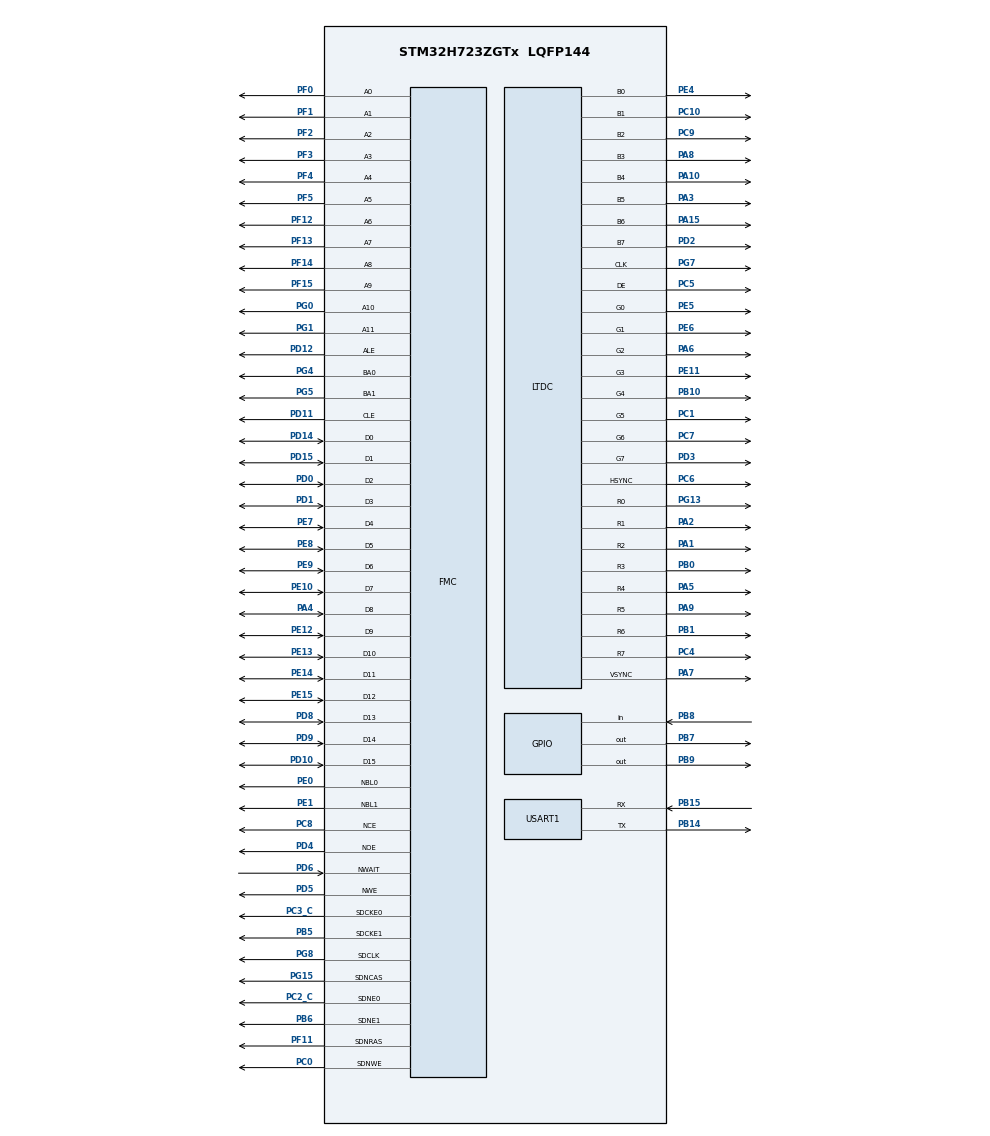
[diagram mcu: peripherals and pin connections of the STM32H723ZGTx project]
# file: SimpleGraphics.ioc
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CORTEX_M7.default_mode_Activation=1
DMA2D.AlphaModeForeground=DMA2D_COMBINE_ALPHA
Dma.MEMTOMEM.2.Direction=DMA_MEMORY_TO_MEMORY
Dma.MEMTOMEM.2.EventEnable=DISABLE
Dma.MEMTOMEM.2.FIFOMode=DMA_FIFOMODE_ENABLE
Dma.MEMTOMEM.2.FIFOThreshold=DMA_FIFO_THRESHOLD_FULL
Dma.MEMTOMEM.2.Instance=DMA1_Stream2
Dma.MEMTOMEM.2.MemBurst=DMA_MBURST_SINGLE
Dma.MEMTOMEM.2.MemDataAlignment=DMA_MDATAALIGN_BYTE
Dma.MEMTOMEM.2.MemInc=DMA_MINC_ENABLE
Dma.MEMTOMEM.2.Mode=DMA_NORMAL
Dma.MEMTOMEM.2.PeriphBurst=DMA_PBURST_SINGLE
Dma.MEMTOMEM.2.PeriphDataAlignment=DMA_PDATAALIGN_BYTE
Dma.MEMTOMEM.2.PeriphInc=DMA_PINC_ENABLE
Dma.MEMTOMEM.2.Polarity=HAL_DMAMUX_REQ_GEN_RISING
Dma.MEMTOMEM.2.Priority=DMA_PRIORITY_VERY_HIGH
Dma.MEMTOMEM.2.RequestNumber=1
Dma.MEMTOMEM.2.SignalID=NONE
Dma.MEMTOMEM.2.SyncEnable=DISABLE
Dma.MEMTOMEM.2.SyncPolarity=HAL_DMAMUX_SYNC_NO_EVENT
Dma.MEMTOMEM.2.SyncRequestNumber=1
Dma.MEMTOMEM.2.SyncSignalID=NONE
Dma.MEMTOMEM.3.Direction=DMA_MEMORY_TO_MEMORY
Dma.MEMTOMEM.3.EventEnable=DISABLE
Dma.MEMTOMEM.3.FIFOMode=DMA_FIFOMODE_ENABLE
Dma.MEMTOMEM.3.FIFOThreshold=DMA_FIFO_THRESHOLD_FULL
Dma.MEMTOMEM.3.Instance=DMA1_Stream3
Dma.MEMTOMEM.3.MemBurst=DMA_MBURST_SINGLE
Dma.MEMTOMEM.3.MemDataAlignment=DMA_MDATAALIGN_BYTE
Dma.MEMTOMEM.3.MemInc=DMA_MINC_ENABLE
Dma.MEMTOMEM.3.Mode=DMA_NORMAL
Dma.MEMTOMEM.3.PeriphBurst=DMA_PBURST_SINGLE
Dma.MEMTOMEM.3.PeriphDataAlignment=DMA_PDATAALIGN_BYTE
Dma.MEMTOMEM.3.PeriphInc=DMA_PINC_ENABLE
Dma.MEMTOMEM.3.Polarity=HAL_DMAMUX_REQ_GEN_RISING
Dma.MEMTOMEM.3.Priority=DMA_PRIORITY_VERY_HIGH
Dma.MEMTOMEM.3.RequestNumber=1
Dma.MEMTOMEM.3.SignalID=NONE
Dma.MEMTOMEM.3.SyncEnable=DISABLE
Dma.MEMTOMEM.3.SyncPolarity=HAL_DMAMUX_SYNC_NO_EVENT
Dma.MEMTOMEM.3.SyncRequestNumber=1
Dma.MEMTOMEM.3.SyncSignalID=NONE
Dma.MEMTOMEM.4.Direction=DMA_MEMORY_TO_MEMORY
Dma.MEMTOMEM.4.EventEnable=DISABLE
Dma.MEMTOMEM.4.FIFOMode=DMA_FIFOMODE_ENABLE
Dma.MEMTOMEM.4.FIFOThreshold=DMA_FIFO_THRESHOLD_FULL
Dma.MEMTOMEM.4.Instance=DMA1_Stream4
Dma.MEMTOMEM.4.MemBurst=DMA_MBURST_SINGLE
Dma.MEMTOMEM.4.MemDataAlignment=DMA_MDATAALIGN_BYTE
Dma.MEMTOMEM.4.MemInc=DMA_MINC_ENABLE
Dma.MEMTOMEM.4.Mode=DMA_NORMAL
Dma.MEMTOMEM.4.PeriphBurst=DMA_PBURST_SINGLE
Dma.MEMTOMEM.4.PeriphDataAlignment=DMA_PDATAALIGN_BYTE
Dma.MEMTOMEM.4.PeriphInc=DMA_PINC_ENABLE
Dma.MEMTOMEM.4.Polarity=HAL_DMAMUX_REQ_GEN_RISING
Dma.MEMTOMEM.4.Priority=DMA_PRIORITY_VERY_HIGH
Dma.MEMTOMEM.4.RequestNumber=1
Dma.MEMTOMEM.4.SignalID=NONE
Dma.MEMTOMEM.4.SyncEnable=DISABLE
Dma.MEMTOMEM.4.SyncPolarity=HAL_DMAMUX_SYNC_NO_EVENT
Dma.MEMTOMEM.4.SyncRequestNumber=1
Dma.MEMTOMEM.4.SyncSignalID=NONE
Dma.Request0=USART1_RX
Dma.Request1=USART1_TX
Dma.Request2=MEMTOMEM
Dma.Request3=MEMTOMEM
Dma.Request4=MEMTOMEM
Dma.USART1_RX.0.Direction=DMA_PERIPH_TO_MEMORY
Dma.USART1_RX.0.EventEnable=DISABLE
Dma.USART1_RX.0.FIFOMode=DMA_FIFOMODE_DISABLE
Dma.USART1_RX.0.Instance=DMA1_Stream0
Dma.USART1_RX.0.MemDataAlignment=DMA_MDATAALIGN_BYTE
Dma.USART1_RX.0.MemInc=DMA_MINC_ENABLE
Dma.USART1_RX.0.Mode=DMA_NORMAL
Dma.USART1_RX.0.PeriphDataAlignment=DMA_PDATAALIGN_BYTE
Dma.USART1_RX.0.PeriphInc=DMA_PINC_DISABLE
Dma.USART1_RX.0.Polarity=HAL_DMAMUX_REQ_GEN_RISING
Dma.USART1_RX.0.Priority=DMA_PRIORITY_VERY_HIGH
Dma.USART1_RX.0.RequestNumber=1
Dma.USART1_RX.0.SignalID=NONE
Dma.USART1_RX.0.SyncEnable=DISABLE
Dma.USART1_RX.0.SyncPolarity=HAL_DMAMUX_SYNC_NO_EVENT
Dma.USART1_RX.0.SyncRequestNumber=1
Dma.USART1_RX.0.SyncSignalID=NONE
Dma.USART1_TX.1.Direction=DMA_MEMORY_TO_PERIPH
Dma.USART1_TX.1.EventEnable=DISABLE
Dma.USART1_TX.1.FIFOMode=DMA_FIFOMODE_DISABLE
Dma.USART1_TX.1.Instance=DMA1_Stream1
Dma.USART1_TX.1.MemDataAlignment=DMA_MDATAALIGN_BYTE
Dma.USART1_TX.1.MemInc=DMA_MINC_ENABLE
Dma.USART1_TX.1.Mode=DMA_NORMAL
Dma.USART1_TX.1.PeriphDataAlignment=DMA_PDATAALIGN_BYTE
Dma.USART1_TX.1.PeriphInc=DMA_PINC_DISABLE
Dma.USART1_TX.1.Polarity=HAL_DMAMUX_REQ_GEN_RISING
Dma.USART1_TX.1.Priority=DMA_PRIORITY_VERY_HIGH
Dma.USART1_TX.1.RequestNumber=1
Dma.USART1_TX.1.SignalID=NONE
Dma.USART1_TX.1.SyncEnable=DISABLE
Dma.USART1_TX.1.SyncPolarity=HAL_DMAMUX_SYNC_NO_EVENT
Dma.USART1_TX.1.SyncRequestNumber=1
Dma.USART1_TX.1.SyncSignalID=NONE
LTDC.DEPolarity=LTDC_DEPOLARITY_AH
LTDC.HSPolarity=LTDC_HSPOLARITY_AH
LTDC.PCPolarity=LTDC_PCPOLARITY_IPC
LTDC.VSPolarity=LTDC_VSPOLARITY_AH
Mcu.Family=STM32H7
Mcu.Name=STM32H723ZGTx
Mcu.Package=LQFP144
NVIC.DMA1_Stream0_IRQn=true\:0\:0\:false\:false\:true\:false\:true\:true
NVIC.DMA1_Stream1_IRQn=true\:0\:0\:false\:false\:true\:false\:true\:true
NVIC.DMA2D_IRQn=true\:0\:0\:false\:false\:true\:true\:true\:true
NVIC.FMC_IRQn=true\:0\:0\:false\:false\:true\:true\:true\:true
NVIC.LTDC_IRQn=true\:0\:0\:false\:false\:true\:true\:true\:true
NVIC.PriorityGroup=NVIC_PRIORITYGROUP_4
NVIC.USART1_IRQn=true\:0\:0\:false\:false\:true\:true\:true\:true
PA1.Mode=RGB888
PA1.Signal=LTDC_R2
PA10.Mode=RGB888
PA10.Signal=LTDC_B4
PA15(JTDI).Mode=RGB888
PA15(JTDI).Signal=LTDC_B6
PA2.Mode=RGB888
PA2.Signal=LTDC_R1
PA3.Mode=RGB888
PA3.Signal=LTDC_B5
PA4.Signal=FMC_D8_DA8
PA5.Mode=RGB888
PA5.Signal=LTDC_R4
PA6.Mode=RGB888
PA6.Signal=LTDC_G2
PA7.Mode=RGB888
PA7.Signal=LTDC_VSYNC
PA8.Mode=RGB888
PA8.Signal=LTDC_B3
PA9.Mode=RGB888
PA9.Signal=LTDC_R5
PB0.Mode=RGB888
PB0.Signal=LTDC_R3
PB1.Mode=RGB888
PB1.Signal=LTDC_R6
PB10.Mode=RGB888
PB10.Signal=LTDC_G4
PB14.Mode=Asynchronous
PB14.Signal=USART1_TX
PB15.Mode=Asynchronous
PB15.Signal=USART1_RX
PB5.Mode=SdramChipSelect2_2
PB5.Signal=FMC_SDCKE1
PB6.Mode=SdramChipSelect2_2
PB6.Signal=FMC_SDNE1
PB7.Signal=GPIO_Output
PB8.Signal=GPIO_Input
PB9.Signal=GPIO_Output
PC0.Signal=FMC_SDNWE
PC1.Mode=RGB888
PC1.Signal=LTDC_G5
PC10.Mode=RGB888
PC10.Signal=LTDC_B1
PC14-OSC32_IN.Mode=LSE-External-Oscillator
PC14-OSC32_IN.Signal=RCC_OSC32_IN
PC15-OSC32_OUT.Mode=LSE-External-Oscillator
PC15-OSC32_OUT.Signal=RCC_OSC32_OUT
PC2_C.Mode=SdramChipSelect1_1
PC2_C.Signal=FMC_SDNE0
PC3_C.Mode=SdramChipSelect1_1
PC3_C.Signal=FMC_SDCKE0
PC4.Mode=RGB888
PC4.Signal=LTDC_R7
PC5.Mode=RGB888
PC5.Signal=LTDC_DE
PC6.Mode=RGB888
PC6.Signal=LTDC_HSYNC
PC7.Mode=RGB888
PC7.Signal=LTDC_G6
PC8.Mode=NandChipSelect3_1
PC8.Signal=FMC_NCE
PC9.Mode=RGB888
PC9.Signal=LTDC_B2
PD0.Signal=FMC_D2_DA2
PD1.Signal=FMC_D3_DA3
PD10.Signal=FMC_D15_DA15
PD11.Signal=FMC_A16_CLE
PD12.Signal=FMC_A17_ALE
PD14.Signal=FMC_D0_DA0
PD15.Signal=FMC_D1_DA1
PD2.Mode=RGB888
PD2.Signal=LTDC_B7
PD3.Mode=RGB888
PD3.Signal=LTDC_G7
PD4.Signal=FMC_NOE
PD5.Signal=FMC_NWE
PD6.Signal=FMC_NWAIT
PD8.Signal=FMC_D13_DA13
PD9.Signal=FMC_D14_DA14
PE0.Signal=FMC_NBL0
PE1.Signal=FMC_NBL1
PE10.Signal=FMC_D7_DA7
PE11.Mode=RGB888
PE11.Signal=LTDC_G3
PE12.Signal=FMC_D9_DA9
PE13.Signal=FMC_D10_DA10
PE14.Signal=FMC_D11_DA11
PE15.Signal=FMC_D12_DA12
PE4.Mode=RGB888
PE4.Signal=LTDC_B0
PE5.Mode=RGB888
PE5.Signal=LTDC_G0
PE6.Mode=RGB888
PE6.Signal=LTDC_G1
PE7.Signal=FMC_D4_DA4
PE8.Signal=FMC_D5_DA5
PE9.Signal=FMC_D6_DA6
PF0.Signal=FMC_A0
PF1.Signal=FMC_A1
PF11.Signal=FMC_SDNRAS
PF12.Signal=FMC_A6
PF13.Signal=FMC_A7
PF14.Signal=FMC_A8
PF15.Signal=FMC_A9
PF2.Signal=FMC_A2
PF3.Signal=FMC_A3
PF4.Signal=FMC_A4
PF5.Signal=FMC_A5
PG0.Signal=FMC_A10
PG1.Signal=FMC_A11
PG13.Mode=RGB888
PG13.Signal=LTDC_R0
PG15.Signal=FMC_SDNCAS
PG4.Signal=FMC_A14_BA0
PG5.Signal=FMC_A15_BA1
PG7.Mode=RGB888
PG7.Signal=LTDC_CLK
PG8.Signal=FMC_SDCLK
PH0-OSC_IN.Mode=HSE-External-Oscillator
PH0-OSC_IN.Signal=RCC_OSC_IN
PH1-OSC_OUT.Mode=HSE-External-Oscillator
PH1-OSC_OUT.Signal=RCC_OSC_OUT
ProjectManager.HeapSize=0x1000
ProjectManager.StackSize=0x1000
ProjectManager.TargetToolchain=Makefile
RCC.ADCFreq_Value=50390625
RCC.APB1Freq_Value=137500000
RCC.APB2Freq_Value=137500000
RCC.APB3Freq_Value=137500000
RCC.APB4Freq_Value=137500000
RCC.CortexFreq_Value=550000000
RCC.D1PPRE=RCC_APB3_DIV2
RCC.D2PPRE1=RCC_APB1_DIV2
RCC.D2PPRE2=RCC_APB2_DIV2
RCC.D3PPRE=RCC_APB4_DIV2
RCC.DIVM1=2
RCC.DIVM3=1
RCC.DIVN1=44
RCC.DIVN3=4
RCC.DIVP1=1
RCC.DIVQ1=5
RCC.HCLKFreq_Value=275000000
RCC.HPRE=RCC_HCLK_DIV2
RCC.PLL2FRACN=0
RCC.PLL3FRACN=0
RCC.PLLFRACN=0
RCC.PLLSourceVirtual=RCC_PLLSOURCE_HSE
RCC.SYSCLKFreq_VALUE=550000000
RCC.SYSCLKSource=RCC_SYSCLKSOURCE_PLLCLK
RCC.USBFreq_Value=110000000
SH.FMC_A0.0=FMC_A0,12b-sda1
SH.FMC_A0.1=FMC_A0,12b-sda2
SH.FMC_A1.0=FMC_A1,12b-sda1
SH.FMC_A1.1=FMC_A1,12b-sda2
SH.FMC_A10.0=FMC_A10,12b-sda1
SH.FMC_A10.1=FMC_A10,12b-sda2
SH.FMC_A11.0=FMC_A11,12b-sda1
SH.FMC_A11.1=FMC_A11,12b-sda2
SH.FMC_A14_BA0.0=FMC_BA0,FourSdramBanks1
SH.FMC_A14_BA0.1=FMC_BA0,FourSdramBanks2
SH.FMC_A15_BA1.0=FMC_BA1,FourSdramBanks1
SH.FMC_A15_BA1.1=FMC_BA1,FourSdramBanks2
SH.FMC_A16_CLE.0=FMC_CLE,8b-dmux1
SH.FMC_A17_ALE.0=FMC_ALE,8b-dmux1
SH.FMC_A2.0=FMC_A2,12b-sda1
SH.FMC_A2.1=FMC_A2,12b-sda2
SH.FMC_A3.0=FMC_A3,12b-sda1
SH.FMC_A3.1=FMC_A3,12b-sda2
SH.FMC_A4.0=FMC_A4,12b-sda1
SH.FMC_A4.1=FMC_A4,12b-sda2
SH.FMC_A5.0=FMC_A5,12b-sda1
SH.FMC_A5.1=FMC_A5,12b-sda2
SH.FMC_A6.0=FMC_A6,12b-sda1
SH.FMC_A6.1=FMC_A6,12b-sda2
SH.FMC_A7.0=FMC_A7,12b-sda1
SH.FMC_A7.1=FMC_A7,12b-sda2
SH.FMC_A8.0=FMC_A8,12b-sda1
SH.FMC_A8.1=FMC_A8,12b-sda2
SH.FMC_A9.0=FMC_A9,12b-sda1
SH.FMC_A9.1=FMC_A9,12b-sda2
SH.FMC_D0_DA0.0=FMC_D0,sd-16b-d1
SH.FMC_D0_DA0.1=FMC_D0,sd-16b-d2
SH.FMC_D0_DA0.2=FMC_D0,8b-dmux1
SH.FMC_D10_DA10.0=FMC_D10,sd-16b-d1
SH.FMC_D10_DA10.1=FMC_D10,sd-16b-d2
SH.FMC_D11_DA11.0=FMC_D11,sd-16b-d1
SH.FMC_D11_DA11.1=FMC_D11,sd-16b-d2
SH.FMC_D12_DA12.0=FMC_D12,sd-16b-d1
SH.FMC_D12_DA12.1=FMC_D12,sd-16b-d2
SH.FMC_D13_DA13.0=FMC_D13,sd-16b-d1
SH.FMC_D13_DA13.1=FMC_D13,sd-16b-d2
SH.FMC_D14_DA14.0=FMC_D14,sd-16b-d1
SH.FMC_D14_DA14.1=FMC_D14,sd-16b-d2
SH.FMC_D15_DA15.0=FMC_D15,sd-16b-d1
SH.FMC_D15_DA15.1=FMC_D15,sd-16b-d2
SH.FMC_D1_DA1.0=FMC_D1,sd-16b-d1
SH.FMC_D1_DA1.1=FMC_D1,sd-16b-d2
SH.FMC_D1_DA1.2=FMC_D1,8b-dmux1
SH.FMC_D2_DA2.0=FMC_D2,sd-16b-d1
SH.FMC_D2_DA2.1=FMC_D2,sd-16b-d2
SH.FMC_D2_DA2.2=FMC_D2,8b-dmux1
SH.FMC_D3_DA3.0=FMC_D3,sd-16b-d1
SH.FMC_D3_DA3.1=FMC_D3,sd-16b-d2
SH.FMC_D3_DA3.2=FMC_D3,8b-dmux1
SH.FMC_D4_DA4.0=FMC_D4,sd-16b-d1
SH.FMC_D4_DA4.1=FMC_D4,sd-16b-d2
SH.FMC_D4_DA4.2=FMC_D4,8b-dmux1
SH.FMC_D5_DA5.0=FMC_D5,sd-16b-d1
SH.FMC_D5_DA5.1=FMC_D5,sd-16b-d2
SH.FMC_D5_DA5.2=FMC_D5,8b-dmux1
SH.FMC_D6_DA6.0=FMC_D6,sd-16b-d1
SH.FMC_D6_DA6.1=FMC_D6,sd-16b-d2
SH.FMC_D6_DA6.2=FMC_D6,8b-dmux1
SH.FMC_D7_DA7.0=FMC_D7,sd-16b-d1
SH.FMC_D7_DA7.1=FMC_D7,sd-16b-d2
SH.FMC_D7_DA7.2=FMC_D7,8b-dmux1
SH.FMC_D8_DA8.0=FMC_D8,sd-16b-d1
SH.FMC_D8_DA8.1=FMC_D8,sd-16b-d2
SH.FMC_D9_DA9.0=FMC_D9,sd-16b-d1
SH.FMC_D9_DA9.1=FMC_D9,sd-16b-d2
SH.FMC_NBL0.0=FMC_NBL0,Sd2ByteEnable1
SH.FMC_NBL0.1=FMC_NBL0,Sd2ByteEnable2
SH.FMC_NBL1.0=FMC_NBL1,Sd2ByteEnable1
SH.FMC_NBL1.1=FMC_NBL1,Sd2ByteEnable2
SH.FMC_NOE.0=FMC_NOE,8b-dmux1
SH.FMC_NWAIT.0=FMC_NWAIT,Wait1
SH.FMC_NWE.0=FMC_NWE,8b-dmux1
SH.FMC_SDCLK.0=FMC_SDCLK,12b-sda1
SH.FMC_SDCLK.1=FMC_SDCLK,12b-sda2
SH.FMC_SDNCAS.0=FMC_SDNCAS,12b-sda1
SH.FMC_SDNCAS.1=FMC_SDNCAS,12b-sda2
SH.FMC_SDNRAS.0=FMC_SDNRAS,12b-sda1
SH.FMC_SDNRAS.1=FMC_SDNRAS,12b-sda2
SH.FMC_SDNWE.0=FMC_SDNWE,12b-sda1
SH.FMC_SDNWE.1=FMC_SDNWE,12b-sda2
USART1.AutoBaudRateEnableParam=UART_ADVFEATURE_AUTOBAUDRATE_DISABLE
USART1.VirtualMode-Asynchronous=VM_ASYNC
VP_DMA2D_VS_DMA2D.Mode=DMA2D_Activate
VP_PWR_V_PVD_IN.Mode=Mode_PVD_Int
VP_RCC_LSE.Mode=CRS SYNC Source LSE
board=custom

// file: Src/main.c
/* USER CODE BEGIN Header */
/**
  ******************************************************************************
  * @file           : main.c
  * @brief          : Main program body
  ******************************************************************************
  * @attention
  *
  * Copyright (c) 2024 STMicroelectronics.
  * All rights reserved.
  *
  * This software is licensed under terms that can be found in the LICENSE file
  * in the root directory of this software component.
  * If no LICENSE file comes with this software, it is provided AS-IS.
  *
  ******************************************************************************
  */
/* USER CODE END Header */
#include "main.h"
#include "dma.h"
#include "dma2d.h"
#include "ltdc.h"
#include "usart.h"
#include "gpio.h"
#include "fmc.h"

/* USER CODE BEGIN Includes */
TIM_TypeDef Time2;
extern void setup();
/* USER CODE END Includes */

void SystemClock_Config(void);
static void MPU_Config(void);

int main(void)
{

  /* MPU Configuration--------------------------------------------------------*/
  MPU_Config();

  /* MCU Configuration--------------------------------------------------------*/

  /* Reset of all peripherals, Initializes the Flash interface and the Systick. */
  HAL_Init();

  /* Configure the system clock */
  SystemClock_Config();

  /* Initialize all configured peripherals */
  MX_GPIO_Init();
  MX_DMA_Init();
  MX_USART1_UART_Init();
  MX_FMC_Init();
  MX_DMA2D_Init();
  MX_LTDC_Init();

  setup();

  /* Infinite loop */
  while (1)
  {

  }
}

void SystemClock_Config(void)
{
  RCC_OscInitTypeDef RCC_OscInitStruct = {0};
  RCC_ClkInitTypeDef RCC_ClkInitStruct = {0};
  RCC_CRSInitTypeDef RCC_CRSInitStruct = {0};

  /** Supply configuration update enable
  */
  HAL_PWREx_ConfigSupply(PWR_LDO_SUPPLY);

  /** Configure the main internal regulator output voltage
  */
  __HAL_PWR_VOLTAGESCALING_CONFIG(PWR_REGULATOR_VOLTAGE_SCALE0);

  while(!__HAL_PWR_GET_FLAG(PWR_FLAG_VOSRDY)) {}

  /** Configure LSE Drive Capability
  */
  HAL_PWR_EnableBkUpAccess();
  __HAL_RCC_LSEDRIVE_CONFIG(RCC_LSEDRIVE_LOW);

  /** Initializes the RCC Oscillators according to the specified parameters
  * in the RCC_OscInitTypeDef structure.
  */
  RCC_OscInitStruct.OscillatorType = RCC_OSCILLATORTYPE_HSI48|RCC_OSCILLATORTYPE_HSE
                              |RCC_OSCILLATORTYPE_LSE;
  RCC_OscInitStruct.HSEState = RCC_HSE_ON;
  RCC_OscInitStruct.LSEState = RCC_LSE_ON;
  RCC_OscInitStruct.HSI48State = RCC_HSI48_ON;
  RCC_OscInitStruct.PLL.PLLState = RCC_PLL_ON;
  RCC_OscInitStruct.PLL.PLLSource = RCC_PLLSOURCE_HSE;
  RCC_OscInitStruct.PLL.PLLM = 2;
  RCC_OscInitStruct.PLL.PLLN = 44;
  RCC_OscInitStruct.PLL.PLLP = 1;
  RCC_OscInitStruct.PLL.PLLQ = 5;
  RCC_OscInitStruct.PLL.PLLR = 2;
  RCC_OscInitStruct.PLL.PLLRGE = RCC_PLL1VCIRANGE_3;
  RCC_OscInitStruct.PLL.PLLVCOSEL = RCC_PLL1VCOWIDE;
  RCC_OscInitStruct.PLL.PLLFRACN = 0;
  if (HAL_RCC_OscConfig(&RCC_OscInitStruct) != HAL_OK)
  {
    Error_Handler();
  }

  /** Initializes the CPU, AHB and APB buses clocks
  */
  RCC_ClkInitStruct.ClockType = RCC_CLOCKTYPE_HCLK|RCC_CLOCKTYPE_SYSCLK
                              |RCC_CLOCKTYPE_PCLK1|RCC_CLOCKTYPE_PCLK2
                              |RCC_CLOCKTYPE_D3PCLK1|RCC_CLOCKTYPE_D1PCLK1;
  RCC_ClkInitStruct.SYSCLKSource = RCC_SYSCLKSOURCE_PLLCLK;
  RCC_ClkInitStruct.SYSCLKDivider = RCC_SYSCLK_DIV1;
  RCC_ClkInitStruct.AHBCLKDivider = RCC_HCLK_DIV2;
  RCC_ClkInitStruct.APB3CLKDivider = RCC_APB3_DIV2;
  RCC_ClkInitStruct.APB1CLKDivider = RCC_APB1_DIV2;
  RCC_ClkInitStruct.APB2CLKDivider = RCC_APB2_DIV2;
  RCC_ClkInitStruct.APB4CLKDivider = RCC_APB4_DIV2;

  if (HAL_RCC_ClockConfig(&RCC_ClkInitStruct, FLASH_LATENCY_3) != HAL_OK)
  {
    Error_Handler();
  }

  /** Enable the SYSCFG APB clock
  */
  __HAL_RCC_CRS_CLK_ENABLE();

  /** Configures CRS
  */
  RCC_CRSInitStruct.Prescaler = RCC_CRS_SYNC_DIV1;
  RCC_CRSInitStruct.Source = RCC_CRS_SYNC_SOURCE_LSE;
  RCC_CRSInitStruct.Polarity = RCC_CRS_SYNC_POLARITY_RISING;
  RCC_CRSInitStruct.ReloadValue = __HAL_RCC_CRS_RELOADVALUE_CALCULATE(48000000,32768);
  RCC_CRSInitStruct.ErrorLimitValue = 34;
  RCC_CRSInitStruct.HSI48CalibrationValue = 32;

  HAL_RCCEx_CRSConfig(&RCC_CRSInitStruct);
}

 /* MPU Configuration */

void MPU_Config(void)
{
  MPU_Region_InitTypeDef MPU_InitStruct = {0};

  /* Disables the MPU */
  HAL_MPU_Disable();

  /** Initializes and configures the Region and the memory to be protected
  */
  MPU_InitStruct.Enable = MPU_REGION_ENABLE;
  MPU_InitStruct.Number = MPU_REGION_NUMBER0;
  MPU_InitStruct.BaseAddress = 0x0;
  MPU_InitStruct.Size = MPU_REGION_SIZE_4GB;
  MPU_InitStruct.SubRegionDisable = 0x87;
  MPU_InitStruct.TypeExtField = MPU_TEX_LEVEL0;
  MPU_InitStruct.AccessPermission = MPU_REGION_NO_ACCESS;
  MPU_InitStruct.DisableExec = MPU_INSTRUCTION_ACCESS_DISABLE;
  MPU_InitStruct.IsShareable = MPU_ACCESS_SHAREABLE;
  MPU_InitStruct.IsCacheable = MPU_ACCESS_NOT_CACHEABLE;
  MPU_InitStruct.IsBufferable = MPU_ACCESS_NOT_BUFFERABLE;

  HAL_MPU_ConfigRegion(&MPU_InitStruct);
  /* Enables the MPU */
  HAL_MPU_Enable(MPU_PRIVILEGED_DEFAULT);

}

void Error_Handler(void)
{
  /* USER CODE BEGIN Error_Handler_Debug */
  /* User can add his own implementation to report the HAL error return state */
  __disable_irq();
  while (1);
  /* USER CODE END Error_Handler_Debug */
}
